VERSION "created by canmatrix"

NS_ :

BS_:

BU_: User ADM_PC_LL25 ADM_PC_BC25 ADM_PC_BP25 ADM_PC_BI25

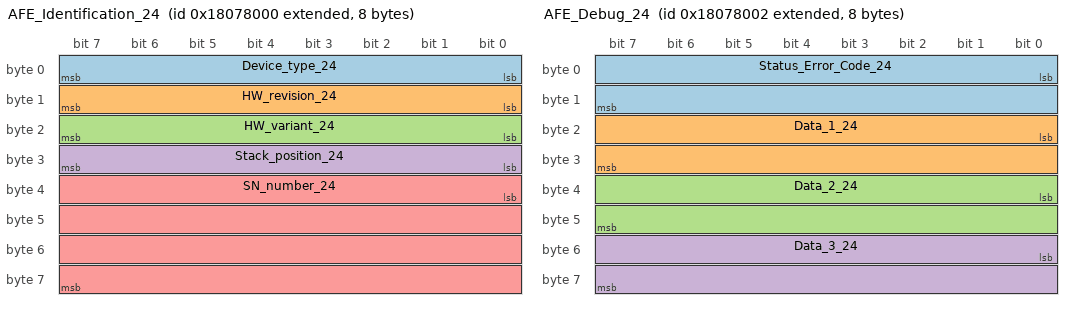
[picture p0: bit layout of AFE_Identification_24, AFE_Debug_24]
BO_ 2550628352 AFE_Identification_24: 8 ADM_PC_BP25
 SG_ Device_type_24 : 0|8@1+ (1,0) [0|255] "" Vector__XXX
 SG_ HW_revision_24 : 8|8@1+ (1,0) [0|255] "" Vector__XXX
 SG_ HW_variant_24 : 16|8@1+ (1,0) [0|255] "" Vector__XXX
 SG_ Stack_position_24 : 24|8@1+ (1,0) [0|255] "" Vector__XXX
 SG_ SN_number_24 : 32|32@1+ (1,0) [0|4294967295] "" Vector__XXX

BO_ 2550628353 AFE_FwInfo_24: 8 ADM_PC_BP25
 SG_ FW_info_mux_24 M : 56|8@1+ (1,0) [0|255] "" Vector__XXX
 SG_ FW_revision_0_24 m0 : 0|8@1+ (1,0) [0|255] "" Vector__XXX
 SG_ FW_revision_1_24 m0 : 8|8@1+ (1,0) [0|255] "" Vector__XXX
 SG_ FW_revision_2_24 m0 : 16|8@1+ (1,0) [0|255] "" Vector__XXX
 SG_ FW_revision_3_24 m0 : 24|8@1+ (1,0) [0|255] "" Vector__XXX
 SG_ FW_revision_4_24 m0 : 32|8@1+ (1,0) [0|255] "" Vector__XXX
 SG_ FW_revision_5_24 m0 : 40|8@1+ (1,0) [0|255] "" Vector__XXX
 SG_ FW_revision_6_24 m0 : 48|8@1+ (1,0) [0|255] "" Vector__XXX
 SG_ FW_revision_7_24 m1 : 0|8@1+ (1,0) [0|255] "" Vector__XXX
 SG_ FW_revision_8_24 m1 : 8|8@1+ (1,0) [0|255] "" Vector__XXX
 SG_ FW_revision_9_24 m1 : 16|8@1+ (1,0) [0|255] "" Vector__XXX
 SG_ FW_revision_10_24 m1 : 24|8@1+ (1,0) [0|255] "" Vector__XXX
 SG_ FW_revision_11_24 m1 : 32|8@1+ (1,0) [0|255] "" Vector__XXX
 SG_ FW_revision_12_24 m1 : 40|8@1+ (1,0) [0|255] "" Vector__XXX
 SG_ FW_revision_13_24 m1 : 48|8@1+ (1,0) [0|255] "" Vector__XXX
 SG_ FW_datecode_0_24 m2 : 0|8@1+ (1,0) [0|255] "" Vector__XXX
 SG_ FW_datecode_1_24 m2 : 8|8@1+ (1,0) [0|255] "" Vector__XXX
 SG_ FW_datecode_2_24 m2 : 16|8@1+ (1,0) [0|255] "" Vector__XXX
 SG_ FW_datecode_3_24 m2 : 24|8@1+ (1,0) [0|255] "" Vector__XXX
 SG_ FW_datecode_4_24 m2 : 32|8@1+ (1,0) [0|255] "" Vector__XXX
 SG_ FW_datecode_5_24 m2 : 40|8@1+ (1,0) [0|255] "" Vector__XXX
 SG_ FW_datecode_6_24 m2 : 48|8@1+ (1,0) [0|255] "" Vector__XXX
 SG_ FW_datecode_7_24 m3 : 0|8@1+ (1,0) [0|255] "" Vector__XXX
 SG_ FW_datecode_8_24 m3 : 8|8@1+ (1,0) [0|255] "" Vector__XXX
 SG_ FW_datecode_9_24 m3 : 16|8@1+ (1,0) [0|255] "" Vector__XXX
 SG_ FW_datecode_10_24 m3 : 24|8@1+ (1,0) [0|255] "" Vector__XXX
 SG_ FW_datecode_11_24 m3 : 32|8@1+ (1,0) [0|255] "" Vector__XXX
 SG_ FW_datecode_12_24 m3 : 40|8@1+ (1,0) [0|255] "" Vector__XXX
 SG_ FW_datecode_13_24 m3 : 48|8@1+ (1,0) [0|255] "" Vector__XXX

BO_ 2550628365 _AFE_Boot_FwInfo_24: 8 ADM_PC_BP25
 SG_ Boot_FW_info_mux_24 M : 56|8@1+ (1,0) [0|255] "" Vector__XXX
 SG_ FW_revision_0_24 m0 : 0|8@1+ (1,0) [0|255] "" Vector__XXX
 SG_ FW_revision_1_24 m0 : 8|8@1+ (1,0) [0|255] "" Vector__XXX
 SG_ FW_revision_2_24 m0 : 16|8@1+ (1,0) [0|255] "" Vector__XXX
 SG_ FW_revision_3_24 m0 : 24|8@1+ (1,0) [0|255] "" Vector__XXX
 SG_ FW_revision_4_24 m0 : 32|8@1+ (1,0) [0|255] "" Vector__XXX
 SG_ FW_revision_5_24 m0 : 40|8@1+ (1,0) [0|255] "" Vector__XXX
 SG_ FW_revision_6_24 m0 : 48|8@1+ (1,0) [0|255] "" Vector__XXX
 SG_ FW_revision_7_24 m1 : 0|8@1+ (1,0) [0|255] "" Vector__XXX
 SG_ FW_revision_8_24 m1 : 8|8@1+ (1,0) [0|255] "" Vector__XXX
 SG_ FW_revision_9_24 m1 : 16|8@1+ (1,0) [0|255] "" Vector__XXX
 SG_ FW_revision_10_24 m1 : 24|8@1+ (1,0) [0|255] "" Vector__XXX
 SG_ FW_revision_11_24 m1 : 32|8@1+ (1,0) [0|255] "" Vector__XXX
 SG_ FW_revision_12_24 m1 : 40|8@1+ (1,0) [0|255] "" Vector__XXX
 SG_ FW_revision_13_24 m1 : 48|8@1+ (1,0) [0|255] "" Vector__XXX
 SG_ FW_datecode_0_24 m2 : 0|8@1+ (1,0) [0|255] "" Vector__XXX
 SG_ FW_datecode_1_24 m2 : 8|8@1+ (1,0) [0|255] "" Vector__XXX
 SG_ FW_datecode_2_24 m2 : 16|8@1+ (1,0) [0|255] "" Vector__XXX
 SG_ FW_datecode_3_24 m2 : 24|8@1+ (1,0) [0|255] "" Vector__XXX
 SG_ FW_datecode_4_24 m2 : 32|8@1+ (1,0) [0|255] "" Vector__XXX
 SG_ FW_datecode_5_24 m2 : 40|8@1+ (1,0) [0|255] "" Vector__XXX
 SG_ FW_datecode_6_24 m2 : 48|8@1+ (1,0) [0|255] "" Vector__XXX
 SG_ FW_datecode_7_24 m3 : 0|8@1+ (1,0) [0|255] "" Vector__XXX
 SG_ FW_datecode_8_24 m3 : 8|8@1+ (1,0) [0|255] "" Vector__XXX
 SG_ FW_datecode_9_24 m3 : 16|8@1+ (1,0) [0|255] "" Vector__XXX
 SG_ FW_datecode_10_24 m3 : 24|8@1+ (1,0) [0|255] "" Vector__XXX
 SG_ FW_datecode_11_24 m3 : 32|8@1+ (1,0) [0|255] "" Vector__XXX
 SG_ FW_datecode_12_24 m3 : 40|8@1+ (1,0) [0|255] "" Vector__XXX
 SG_ FW_datecode_13_24 m3 : 48|8@1+ (1,0) [0|255] "" Vector__XXX

BO_ 2550628354 AFE_Debug_24: 8 ADM_PC_BP25
 SG_ Status_Error_Code_24 : 0|16@1+ (1,0) [0|65535] "" Vector__XXX
 SG_ Data_1_24 : 16|16@1+ (1,0) [0|65535] "" Vector__XXX
 SG_ Data_2_24 : 32|16@1+ (1,0) [0|65535] "" Vector__XXX
 SG_ Data_3_24 : 48|16@1+ (1,0) [0|65535] "" Vector__XXX

BO_ 2550628359 AFE_Status_24: 8 ADM_PC_BP25
 SG_ Running_24 : 0|1@1+ (1,0) [0|1] "" Vector__XXX
 SG_ PWM_24 : 1|1@1+ (1,0) [0|1] "" Vector__XXX
 SG_ Current_dc_loop_mode_24 : 2|1@1+ (1,0) [0|1] "" Vector__XXX
 SG_ Current_ac_loop_mode_24 : 3|1@1+ (1,0) [0|1] "" Vector__XXX
 SG_ Buck_24 : 5|1@1+ (1,0) [0|1] "" Vector__XXX
 SG_ Boost_24 : 6|1@1+ (1,0) [0|1] "" Vector__XXX
 SG_ Precharge_dc_buck_mode_24 : 7|1@1+ (1,0) [0|1] "" Vector__XXX
 SG_ Precharge_dc_boost_mode_24 : 8|1@1+ (1,0) [0|1] "" Vector__XXX
 SG_ Rectifier_3ph_24 : 9|1@1+ (1,0) [0|1] "" Vector__XXX
 SG_ Stack_mode_24 : 10|1@1+ (1,0) [0|1] "" Vector__XXX
 SG_ Master_24 : 11|1@1+ (1,0) [0|1] "" Vector__XXX
 SG_ Slave_24 : 12|1@1+ (1,0) [0|1] "" Vector__XXX
 SG_ Inverter_1ph_24 : 13|1@1+ (1,0) [0|1] "" Vector__XXX
 SG_ Boost_Neutral_24 : 14|1@1+ (1,0) [0|1] "" Vector__XXX
 SG_ Rectifier_1ph_24 : 15|1@1+ (1,0) [0|1] "" Vector__XXX
 SG_ Inverter_3ph_24 : 16|1@1+ (1,0) [0|1] "" Vector__XXX
 SG_ Ready_24 : 17|1@1+ (1,0) [0|1] "" Vector__XXX
 SG_ Inverter_1ph_Sync_24 : 18|1@1+ (1,0) [0|1] "" Vector__XXX
 SG_ Neutral_24 : 19|1@1+ (1,0) [0|1] "" Vector__XXX
 SG_ Rectifier_1ph_Buck_24 : 20|1@1+ (1,0) [0|1] "" Vector__XXX
 SG_ Inverter_1ph_Boost_24 : 21|1@1+ (1,0) [0|1] "" Vector__XXX
 SG_ Rectifier_distributed_24 : 22|1@1+ (1,0) [0|1] "" Vector__XXX
 SG_ MPPT_buck_24 : 23|1@1+ (1,0) [0|1] "" Vector__XXX
 SG_ MPPT_boost_24 : 24|1@1+ (1,0) [0|1] "" Vector__XXX
 SG_ Buck_2p_float_24 : 25|1@1+ (1,0) [0|1] "" Vector__XXX
 SG_ Inverter_1ph_Distributed_24 : 26|1@1+ (1,0) [0|1] "" Vector__XXX

BO_ 2550628358 AFE_Faults_24: 3 ADM_PC_BP25
 SG_ Protection_trip_internal_24 : 0|1@1+ (1,0) [0|1] "" Vector__XXX
 SG_ Protection_trip_external_24 : 1|1@1+ (1,0) [0|1] "" Vector__XXX
 SG_ Phase_U_overcurrent_24 : 2|1@1+ (1,0) [0|1] "" Vector__XXX
 SG_ Phase_U_overvoltage_24 : 3|1@1+ (1,0) [0|1] "" Vector__XXX
 SG_ Phase_U_undervoltage_24 : 4|1@1+ (1,0) [0|1] "" Vector__XXX
 SG_ Phase_V_overvoltage_24 : 5|1@1+ (1,0) [0|1] "" Vector__XXX
 SG_ Phase_V_undervoltage_24 : 6|1@1+ (1,0) [0|1] "" Vector__XXX
 SG_ Phase_V_overcurrent_24 : 7|1@1+ (1,0) [0|1] "" Vector__XXX
 SG_ Phase_W_overvoltage_24 : 8|1@1+ (1,0) [0|1] "" Vector__XXX
 SG_ Phase_W_undervoltage_24 : 9|1@1+ (1,0) [0|1] "" Vector__XXX
 SG_ Phase_W_overcurrent_24 : 10|1@1+ (1,0) [0|1] "" Vector__XXX
 SG_ DC_undervoltage_24 : 11|1@1+ (1,0) [0|1] "" Vector__XXX
 SG_ DC_overvoltage_24 : 12|1@1+ (1,0) [0|1] "" Vector__XXX
 SG_ MOSFET_overtemperature_24 : 13|1@1+ (1,0) [0|1] "" Vector__XXX
 SG_ Inductor_overtemperature_24 : 14|1@1+ (1,0) [0|1] "" Vector__XXX
 SG_ Keep_Alive_not_served_24 : 15|1@1+ (1,0) [0|1] "" Vector__XXX
 SG_ PLL_not_locked_24 : 16|1@1+ (1,0) [0|1] "" Vector__XXX
 SG_ NFO_24 : 20|1@1+ (1,0) [0|1] "" Vector__XXX
 SG_ Measurement_system_failure_24 : 21|1@1+ (1,0) [0|1] "" Vector__XXX
 SG_ EEPROM_failure_24 : 22|1@1+ (1,0) [0|1] "" Vector__XXX
 SG_ System_24 : 23|1@1+ (1,0) [0|1] "" Vector__XXX

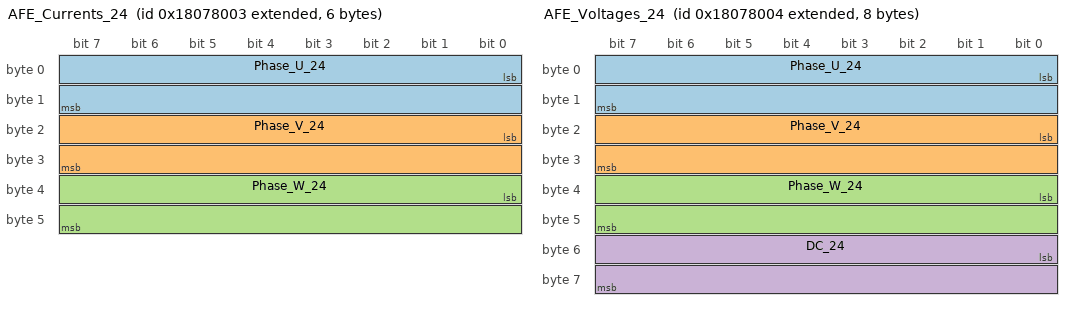
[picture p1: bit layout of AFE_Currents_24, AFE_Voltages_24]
BO_ 2550628355 AFE_Currents_24: 6 ADM_PC_BP25
 SG_ Phase_U_24 : 0|16@1- (0.01,0) [-327.68|327.67] "A" Vector__XXX
 SG_ Phase_V_24 : 16|16@1- (0.01,0) [-327.68|327.67] "A" Vector__XXX
 SG_ Phase_W_24 : 32|16@1- (0.01,0) [-327.68|327.67] "A" Vector__XXX

BO_ 2550628368 AFE_DC_Bus_current_24: 2 ADM_PC_BP25
 SG_ Bus_current_24 : 0|16@1- (0.01,0) [-327.68|327.67] "A" Vector__XXX

BO_ 2550628366 _AFE_Broadcast_24: 8 ADM_PC_BP25
 SG_ Diagnostics_Index_24 M : 56|8@1+ (1,0) [0|255] "" Vector__XXX
 SG_ Phase_U_24 m1 : 8|16@1- (0.01,0) [-327.68|327.67] "A" ADM_PC_BP25
 SG_ Phase_V_24 m1 : 24|16@1- (0.01,0) [-327.68|327.67] "A" ADM_PC_BP25
 SG_ Phase_W_24 m1 : 40|16@1- (0.01,0) [-327.68|327.67] "A" ADM_PC_BP25
 SG_ Stack_position_24 : 0|5@1+ (1,0) [0|31] "" ADM_PC_BP25
 SG_ Group_ID_24 : 5|3@1+ (1,0) [0|7] "" ADM_PC_BP25

BO_ 2550628356 AFE_Voltages_24: 8 ADM_PC_BP25
 SG_ Phase_U_24 : 0|16@1- (0.1,0) [-3276.8|3276.7] "V" Vector__XXX
 SG_ Phase_V_24 : 16|16@1- (0.1,0) [-3276.8|3276.7] "V" Vector__XXX
 SG_ Phase_W_24 : 32|16@1- (0.1,0) [-3276.8|3276.7] "V" Vector__XXX
 SG_ DC_24 : 48|16@1- (0.1,0) [-3276.8|3276.7] "V" Vector__XXX

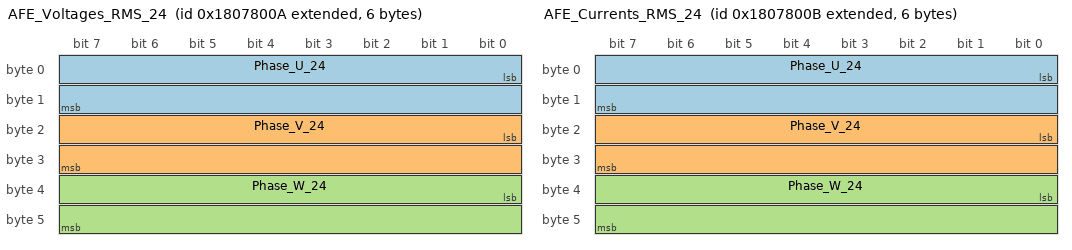
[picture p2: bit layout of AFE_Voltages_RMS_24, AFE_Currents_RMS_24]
BO_ 2550628362 AFE_Voltages_RMS_24: 6 ADM_PC_BP25
 SG_ Phase_U_24 : 0|16@1+ (0.1,0) [0|6553.5] "V" Vector__XXX
 SG_ Phase_V_24 : 16|16@1+ (0.1,0) [0|6553.5] "V" Vector__XXX
 SG_ Phase_W_24 : 32|16@1+ (0.1,0) [0|6553.5] "V" Vector__XXX

BO_ 2550628363 AFE_Currents_RMS_24: 6 ADM_PC_BP25
 SG_ Phase_U_24 : 0|16@1+ (0.01,0) [0.00|655.35] "A" Vector__XXX
 SG_ Phase_V_24 : 16|16@1+ (0.01,0) [0.00|655.35] "A" Vector__XXX
 SG_ Phase_W_24 : 32|16@1+ (0.01,0) [0.00|655.35] "A" Vector__XXX

BO_ 2550628364 AFE_Mains_24: 4 ADM_PC_BP25
 SG_ Frequency_24 : 0|16@1+ (0.01,0) [0.00|655.35] "Hz" Vector__XXX
 SG_ Phase_24 : 16|16@1- (0.1,0) [-3276.8|3276.7] "Deg." Vector__XXX

BO_ 2550628357 AFE_Temperatures_24: 4 ADM_PC_BP25
 SG_ Temp_Bridge_24 : 0|16@1- (0.01,0) [-327.68|327.67] "°C" Vector__XXX
 SG_ Temp_Inductors_24 : 16|16@1- (0.01,0) [-327.68|327.67] "°C" Vector__XXX

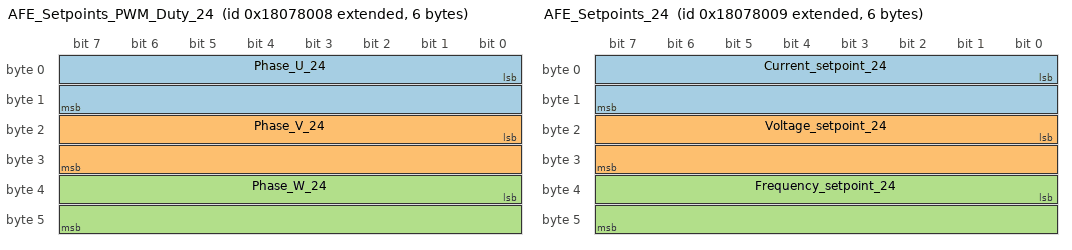
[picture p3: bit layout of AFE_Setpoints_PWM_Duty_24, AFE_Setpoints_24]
BO_ 2550628360 AFE_Setpoints_PWM_Duty_24: 6 ADM_PC_BP25
 SG_ Phase_U_24 : 0|16@1+ (0.001525902,0) [0E-009|99.999987570] "%" Vector__XXX
 SG_ Phase_V_24 : 16|16@1+ (0.001525902,0) [0E-009|99.999987570] "%" Vector__XXX
 SG_ Phase_W_24 : 32|16@1+ (0.001525902,0) [0E-009|99.999987570] "%" Vector__XXX

BO_ 2550628361 AFE_Setpoints_24: 6 ADM_PC_BP25
 SG_ Current_setpoint_24 : 0|16@1- (0.01,0) [-327.68|327.67] "A" Vector__XXX
 SG_ Voltage_setpoint_24 : 16|16@1+ (0.1,0) [0|6553.5] "V" Vector__XXX
 SG_ Frequency_setpoint_24 : 32|16@1+ (0.01,0) [0.00|655.35] "Hz" Vector__XXX

BO_ 2550595680 AFE_Keep_Alive_24: 1 User
 SG_ Keep_Alive_Enable_24 : 0|1@1+ (1,0) [0|1] "" ADM_PC_BP25

BO_ 2550595648 AFE_Mode_Control_24: 8 User
 SG_ Converter_ON_24 : 0|1@1+ (1,0) [0|1] "" ADM_PC_BP25
 SG_ PWM_ON_24 : 1|1@1+ (1,0) [0|1] "" ADM_PC_BP25
 SG_ DC_Current_feedback_ON_24 : 2|1@1+ (1,0) [0|1] "" ADM_PC_BP25
 SG_ AC_Current_feedback_ON_24 : 3|1@1+ (1,0) [0|1] "" ADM_PC_BP25
 SG_ Buck_ON_24 : 5|1@1+ (1,0) [0|1] "" ADM_PC_BP25
 SG_ Boost_ON_24 : 6|1@1+ (1,0) [0|1] "" ADM_PC_BP25
 SG_ Rectifier_3ph_ON_24 : 9|1@1+ (1,0) [0|1] "" ADM_PC_BP25
 SG_ Inverter_1ph_ON_24 : 10|1@1+ (1,0) [0|1] "" ADM_PC_BP25
 SG_ Rectifier_1ph_ON_24 : 11|1@1+ (1,0) [0|1] "" ADM_PC_BP25
 SG_ Boost_Neutral_ON_24 : 12|1@1+ (1,0) [0|1] "" ADM_PC_BP25
 SG_ Inverter_3ph_ON_24 : 13|1@1+ (1,0) [0|1] "" ADM_PC_BP25
 SG_ Inverter_1ph_Sync_ON_24 : 14|1@1+ (1,0) [0|1] "" ADM_PC_BP25
 SG_ Neutral_ON_24 : 15|1@1+ (1,0) [0|1] "" ADM_PC_BP25
 SG_ Rectifier_1ph_Buck_ON_24 : 16|1@1+ (1,0) [0|1] "" ADM_PC_BP25
 SG_ Inverter_1ph_Boost_ON_24 : 17|1@1+ (1,0) [0|1] "" ADM_PC_BP25
 SG_ Rectifier_Distributed_ON_24 : 18|1@1+ (1,0) [0|1] "" ADM_PC_BP25
 SG_ MPPT_buck_ON_24 : 19|1@1+ (1,0) [0|1] "" ADM_PC_BP25
 SG_ MPPT_boost_ON_24 : 20|1@1+ (1,0) [0|1] "" ADM_PC_BP25
 SG_ Buck_2p_float_ON_24 : 21|1@1+ (1,0) [0|1] "" ADM_PC_BP25
 SG_ Inverter_1ph_Distributed_ON_24 : 22|1@1+ (1,0) [0|1] "" ADM_PC_BP25

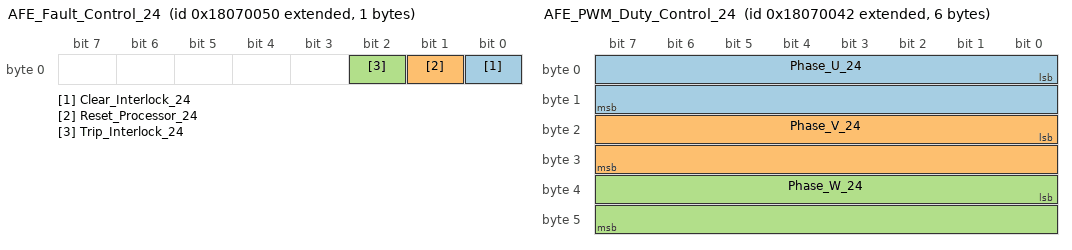
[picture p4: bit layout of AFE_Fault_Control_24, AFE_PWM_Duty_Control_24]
BO_ 2550595664 AFE_Fault_Control_24: 1 User
 SG_ Clear_Interlock_24 : 0|1@1+ (1,0) [0|1] "" ADM_PC_BP25
 SG_ Reset_Processor_24 : 1|1@1+ (1,0) [0|1] "" ADM_PC_BP25
 SG_ Trip_Interlock_24 : 2|1@1+ (1,0) [0|1] "" ADM_PC_BP25

BO_ 2550595649 AFE_Reactive_Current_Setpoint_Co: 2 User
 SG_ Reactive_current_setpoint_24 : 0|16@1- (0.01,0) [-150|150] "A" ADM_PC_BP25

BO_ 2550595650 AFE_PWM_Duty_Control_24: 6 User
 SG_ Phase_U_24 : 0|16@1+ (0.001525902,0) [0E-009|99.999987570] "%" ADM_PC_BP25
 SG_ Phase_V_24 : 16|16@1+ (0.001525902,0) [0E-009|99.999987570] "%" ADM_PC_BP25
 SG_ Phase_W_24 : 32|16@1+ (0.001525902,0) [0E-009|99.999987570] "%" ADM_PC_BP25

BO_ 2550595651 AFE_Current_Setpoint_Control_24: 2 User
 SG_ Current_setpoint_24 : 0|16@1- (0.01,0) [-150|150] "A" ADM_PC_BP25

BO_ 2550595652 AFE_Voltage_Setpoint_Control_24: 2 User
 SG_ Voltage_setpoint_24 : 0|16@1+ (0.1,0) [0|1500] "V" ADM_PC_BP25

BO_ 2550595656 AFE_Frequency_Setpoint_Control_2: 2 User
 SG_ Frequency_setpoint_24 : 0|16@1+ (0.01,0) [40|70] "Hz" ADM_PC_BP25

BO_ 2550595657 AFE_Phase_Setpoint_Control_24: 2 User
 SG_ Phase_setpoint_24 : 0|16@1+ (1,0) [0|360] "deg" ADM_PC_BP25

BO_ 2550595696 AFE_Rectifier_Setpoint_Control_2: 8 User
 SG_ Voltage_setpoint_2_24 : 0|16@1+ (0.1,0) [0|1500] "V" ADM_PC_BP25
 SG_ Current_setpoint_2_24 : 16|16@1- (0.01,0) [-150|150] "A" ADM_PC_BP25

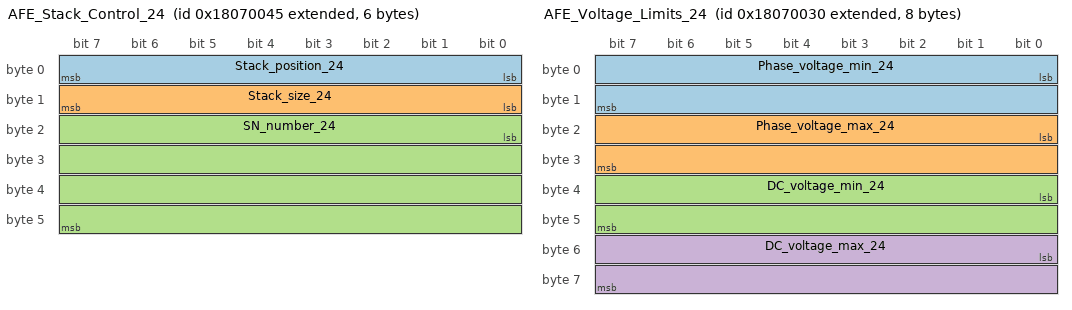
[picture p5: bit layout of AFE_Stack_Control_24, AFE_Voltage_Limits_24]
BO_ 2550595653 AFE_Stack_Control_24: 6 User
 SG_ Stack_position_24 : 0|8@1+ (1,0) [0|255] "" ADM_PC_BP25
 SG_ Stack_size_24 : 8|8@1+ (1,0) [0|255] "" ADM_PC_BP25
 SG_ SN_number_24 : 16|32@1+ (1,0) [0|4294967295] "" ADM_PC_BP25

BO_ 2550595632 AFE_Voltage_Limits_24: 8 User
 SG_ Phase_voltage_min_24 : 0|16@1- (0.1,0) [0|3276.7] "V" ADM_PC_BP25
 SG_ Phase_voltage_max_24 : 16|16@1- (0.1,0) [-3276.8|850] "V" ADM_PC_BP25
 SG_ DC_voltage_min_24 : 32|16@1- (0.1,0) [0|3276.7] "V" ADM_PC_BP25
 SG_ DC_voltage_max_24 : 48|16@1- (0.1,0) [-3276.8|850] "V" ADM_PC_BP25

BO_ 2550595633 AFE_Current_Limits_24: 4 User
 SG_ Phase_current_min_24 : 0|16@1- (0.01,0) [-60|60] "A" ADM_PC_BP25
 SG_ Phase_current_max_24 : 16|16@1- (0.01,0) [-60|60] "A" ADM_PC_BP25

BO_ 2550595660 AFE_Group_Control_24: 1 User
 SG_ Group_ID_24 : 0|8@1+ (1,0) [0|255] "" ADM_PC_BP25

BO_ 2550628367 AFE_Group_Info_24: 1 ADM_PC_BP25
 SG_ Group_ID_24 : 0|8@1+ (1,0) [0|255] "" Vector__XXX

BO_ 2550595681 AFE_System_Flags_Control_24: 8 User
 SG_ Factory_mode_24 : 0|1@1+ (1,0) [0|1] "" ADM_PC_BP25
 SG_ Silent_CAN_mode_24 : 1|1@1+ (1,0) [0|1] "" ADM_PC_BP25

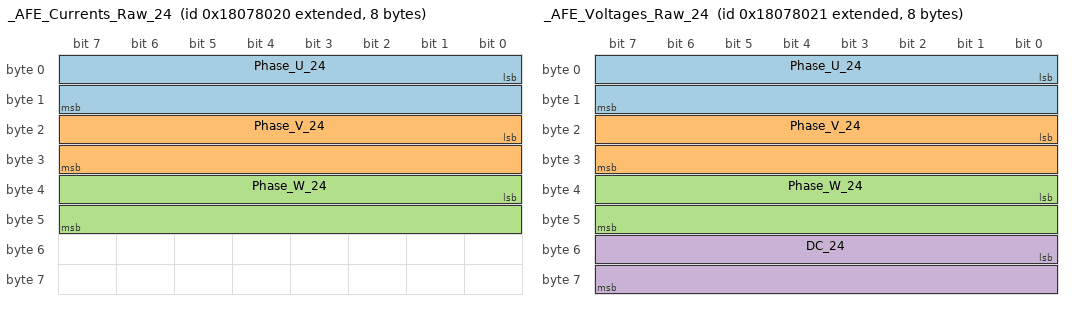
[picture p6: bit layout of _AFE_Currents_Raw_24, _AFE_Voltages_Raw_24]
BO_ 2550628384 _AFE_Currents_Raw_24: 8 ADM_PC_BP25
 SG_ Phase_U_24 : 0|16@1- (1,0) [-32768|32767] "" Vector__XXX
 SG_ Phase_V_24 : 16|16@1- (1,0) [-32768|32767] "" Vector__XXX
 SG_ Phase_W_24 : 32|16@1- (1,0) [-32768|32767] "" Vector__XXX

BO_ 2550628385 _AFE_Voltages_Raw_24: 8 ADM_PC_BP25
 SG_ Phase_U_24 : 0|16@1- (1,0) [-32768|32767] "" Vector__XXX
 SG_ Phase_V_24 : 16|16@1- (1,0) [-32768|32767] "" Vector__XXX
 SG_ Phase_W_24 : 32|16@1- (1,0) [-32768|32767] "" Vector__XXX
 SG_ DC_24 : 48|16@1- (1,0) [-32768|32767] "" Vector__XXX

BO_ 2550595658 _AFE_ADC_Calibration_Mode_24: 1 User
 SG_ Calibration_Index_24 M : 2|5@1+ (1,0) [0|31] "" Vector__XXX
 SG_ Current_U_24 m1 : 0|2@1+ (1,0) [0|3] "" ADM_PC_BP25
 SG_ Current_V_24 m2 : 0|2@1+ (1,0) [0|3] "" ADM_PC_BP25
 SG_ Current_W_24 m3 : 0|2@1+ (1,0) [0|3] "" ADM_PC_BP25
 SG_ Voltage_U_24 m4 : 0|2@1+ (1,0) [0|3] "" ADM_PC_BP25
 SG_ Voltage_V_24 m5 : 0|2@1+ (1,0) [0|3] "" ADM_PC_BP25
 SG_ Voltage_W_24 m6 : 0|2@1+ (1,0) [0|3] "" ADM_PC_BP25
 SG_ Voltage_DC_24 m7 : 0|2@1+ (1,0) [0|3] "" ADM_PC_BP25
 SG_ start_24 : 7|1@1+ (1,0) [0|1] "" ADM_PC_BP25

BO_ 2550595659 _AFE_ADC_Calibration_Setpoint_24: 3 User
 SG_ Calibration_Index_24 M : 16|5@1+ (1,0) [0|31] "" Vector__XXX
 SG_ Current_U_24 m1 : 0|16@1- (0.01,0) [-100|100] "A" ADM_PC_BP25
 SG_ Current_V_24 m2 : 0|16@1- (0.01,0) [-100|100] "A" ADM_PC_BP25
 SG_ Current_W_24 m3 : 0|16@1- (0.01,0) [-100|100] "A" ADM_PC_BP25
 SG_ Voltage_U_24 m4 : 0|16@1+ (0.1,0) [0|1500] "V" ADM_PC_BP25
 SG_ Voltage_V_24 m5 : 0|16@1+ (0.1,0) [0|1500] "V" ADM_PC_BP25
 SG_ Voltage_W_24 m6 : 0|16@1+ (0.1,0) [0|1500] "V" ADM_PC_BP25
 SG_ Voltage_DC_24 m7 : 0|16@1+ (0.1,0) [0|1500] "V" ADM_PC_BP25
 SG_ point_24 : 21|3@1+ (1,0) [0|7] "" ADM_PC_BP25

BO_ 2550595654 _AFE_Calibration_Offset_Update_2: 6 User
 SG_ Calibration_Index_24 M : 16|16@1+ (1,0) [0|65535] "" Vector__XXX
 SG_ Current_U_24 m0 : 0|16@1- (1,0) [-32768|32767] "ADC Counts" ADM_PC_BP25
 SG_ Current_V_24 m1 : 0|16@1- (1,0) [-32768|32767] "ADC Counts" ADM_PC_BP25
 SG_ Current_W_24 m2 : 0|16@1- (1,0) [-32768|32767] "ADC Counts" ADM_PC_BP25
 SG_ Voltage_U_24 m3 : 0|16@1- (1,0) [-32768|32767] "ADC Counts" ADM_PC_BP25
 SG_ Voltage_V_24 m4 : 0|16@1- (1,0) [-32768|32767] "ADC Counts" ADM_PC_BP25
 SG_ Voltage_W_24 m5 : 0|16@1- (1,0) [-32768|32767] "ADC Counts" ADM_PC_BP25
 SG_ Voltage_DC_24 m6 : 0|16@1- (1,0) [-32768|32767] "ADC Counts" ADM_PC_BP25
 SG_ CRC_24 : 32|16@1+ (1,0) [0|65535] "-" ADM_PC_BP25

BO_ 2550595655 _AFE_Calibration_Scale_Update_24: 6 User
 SG_ Calibration_Index_24 M : 16|16@1+ (1,0) [0|65535] "" Vector__XXX
 SG_ Current_U_24 m0 : 0|16@1- (0.0000152587890625,0) [-0.5000000000000000|0.4999847412109375] "scale = 1.0 + value" ADM_PC_BP25
 SG_ Current_V_24 m1 : 0|16@1- (0.0000152587890625,0) [-0.5000000000000000|0.4999847412109375] "scale = 1.0 + value" ADM_PC_BP25
 SG_ Current_W_24 m2 : 0|16@1- (0.0000152587890625,0) [-0.5000000000000000|0.4999847412109375] "scale = 1.0 + value" ADM_PC_BP25
 SG_ Voltage_U_24 m3 : 0|16@1- (0.0000152587890625,0) [-0.5000000000000000|0.4999847412109375] "scale = 1.0 + value" ADM_PC_BP25
 SG_ Voltage_V_24 m4 : 0|16@1- (0.0000152587890625,0) [-0.5000000000000000|0.4999847412109375] "scale = 1.0 + value" ADM_PC_BP25
 SG_ Voltage_W_24 m5 : 0|16@1- (0.0000152587890625,0) [-0.5000000000000000|0.4999847412109375] "scale = 1.0 + value" ADM_PC_BP25
 SG_ Voltage_DC_24 m6 : 0|16@1- (0.0000152587890625,0) [-0.5000000000000000|0.4999847412109375] "scale = 1.0 + value" ADM_PC_BP25
 SG_ CRC_24 : 32|16@1+ (1,0) [0|65535] "-" ADM_PC_BP25

BO_ 2550628433 _AFE_Calibration_Adc_Scale_24: 6 ADM_PC_BP25
 SG_ Adc_Index_24 M : 32|16@1+ (1,0) [0|65535] "" Vector__XXX
 SG_ Current_U_24 m0 : 0|32@1+ (1,0) [0|4294967295] "1 / adc_bins" User
 SG_ Current_V_24 m1 : 0|32@1+ (1,0) [0|4294967295] "1 / adc_bins" User
 SG_ Current_W_24 m2 : 0|32@1+ (1,0) [0|4294967295] "1 / adc_bins" User
 SG_ Voltage_U_24 m3 : 0|32@1+ (1,0) [0|4294967295] "1 / adc_bins" User
 SG_ Voltage_V_24 m4 : 0|32@1+ (1,0) [0|4294967295] "1 / adc_bins" User
 SG_ Voltage_W_24 m5 : 0|32@1+ (1,0) [0|4294967295] "1 / adc_bins" User
 SG_ Voltage_DC_24 m6 : 0|32@1+ (1,0) [0|4294967295] "1 / adc_bins" User

BO_ 2550628434 _AFE_Calibration_Adc_Fs_24: 6 ADM_PC_BP25
 SG_ Adc_Index_24 M : 32|16@1+ (1,0) [0|65535] "" Vector__XXX
 SG_ Current_U_24 m0 : 0|32@1+ (1,0) [0|4294967295] "Fullscale" User
 SG_ Current_V_24 m1 : 0|32@1+ (1,0) [0|4294967295] "Fullscale" User
 SG_ Current_W_24 m2 : 0|32@1+ (1,0) [0|4294967295] "Fullscale" User
 SG_ Voltage_U_24 m3 : 0|32@1+ (1,0) [0|4294967295] "Fullscale" User
 SG_ Voltage_V_24 m4 : 0|32@1+ (1,0) [0|4294967295] "Fullscale" User
 SG_ Voltage_W_24 m5 : 0|32@1+ (1,0) [0|4294967295] "Fullscale" User
 SG_ Voltage_DC_24 m6 : 0|32@1+ (1,0) [0|4294967295] "Fullscale" User

BO_ 2550628435 _AFE_Calibration_Adc_Offset_24: 4 ADM_PC_BP25
 SG_ Adc_Index_24 M : 16|16@1+ (1,0) [0|65535] "" Vector__XXX
 SG_ Current_U_24 m0 : 0|16@1- (1,0) [-32768|32767] "-" User
 SG_ Current_V_24 m1 : 0|16@1- (1,0) [-32768|32767] "-" User
 SG_ Current_W_24 m2 : 0|16@1- (1,0) [-32768|32767] "-" User
 SG_ Voltage_U_24 m3 : 0|16@1- (1,0) [-32768|32767] "-" User
 SG_ Voltage_V_24 m4 : 0|16@1- (1,0) [-32768|32767] "-" User
 SG_ Voltage_W_24 m5 : 0|16@1- (1,0) [-32768|32767] "-" User
 SG_ Voltage_DC_24 m6 : 0|16@1- (1,0) [-32768|32767] "-" User

BO_ 2550628436 _AFE_Calibration_Adc_Gain_24: 4 ADM_PC_BP25
 SG_ Adc_Index_24 M : 16|16@1+ (1,0) [0|65535] "" Vector__XXX
 SG_ Current_U_24 m0 : 0|16@1- (1,0) [-32768|32767] "-" User
 SG_ Current_V_24 m1 : 0|16@1- (1,0) [-32768|32767] "-" User
 SG_ Current_W_24 m2 : 0|16@1- (1,0) [-32768|32767] "-" User
 SG_ Voltage_U_24 m3 : 0|16@1- (1,0) [-32768|32767] "-" User
 SG_ Voltage_V_24 m4 : 0|16@1- (1,0) [-32768|32767] "-" User
 SG_ Voltage_W_24 m5 : 0|16@1- (1,0) [-32768|32767] "-" User
 SG_ Voltage_DC_24 m6 : 0|16@1- (1,0) [-32768|32767] "-" User

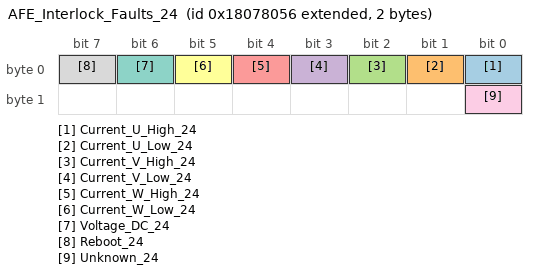
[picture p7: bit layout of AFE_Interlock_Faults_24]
BO_ 2550628438 AFE_Interlock_Faults_24: 2 ADM_PC_BP25
 SG_ Current_U_High_24 : 0|1@1+ (1,0) [0|1] "" Vector__XXX
 SG_ Current_U_Low_24 : 1|1@1+ (1,0) [0|1] "" Vector__XXX
 SG_ Current_V_High_24 : 2|1@1+ (1,0) [0|1] "" Vector__XXX
 SG_ Current_V_Low_24 : 3|1@1+ (1,0) [0|1] "" Vector__XXX
 SG_ Current_W_High_24 : 4|1@1+ (1,0) [0|1] "" Vector__XXX
 SG_ Current_W_Low_24 : 5|1@1+ (1,0) [0|1] "" Vector__XXX
 SG_ Voltage_DC_24 : 6|1@1+ (1,0) [0|1] "" Vector__XXX
 SG_ Reboot_24 : 7|1@1+ (1,0) [0|1] "" Vector__XXX
 SG_ Unknown_24 : 8|1@1+ (1,0) [0|1] "" Vector__XXX

BO_TX_BU_ 2550595648 : User,ADM_PC_LL25,ADM_PC_BC25,ADM_PC_BI25;
BO_TX_BU_ 2550595651 : User,ADM_PC_LL25,ADM_PC_BC25,ADM_PC_BI25;
BO_TX_BU_ 2550595652 : User,ADM_PC_LL25,ADM_PC_BC25,ADM_PC_BI25;
CM_ BO_ 2550628352  "Identification of the device";
CM_ BO_ 2550628353  "Git revision of the DSP firmware";
CM_ BO_ 2550628365  "Git revision of the bootloader firmware.";
CM_ BO_ 2550628354  "Values for debugging of HW/SW problems";
CM_ BO_ 2550628359  "Status bitfield";
CM_ BO_ 2550628358  "Fault bitfield";
CM_ BO_ 2550628355  "Current of phases U, V, W";
CM_ BO_ 2550628368  "Current of of the DC Bus";
CM_ BO_ 2550628366  "All AFEs will listen to this message";
CM_ BO_ 2550628363  "RMS Current of phases U, V, W";
CM_ BO_ 2550628364  "Three-Phase mains health (frequency, phase...)";
CM_ BO_ 2550628357  "Readouts of the module temperature sensors";
CM_ BO_ 2550628360  "Setpoints";
CM_ BO_ 2550628361  "Setpoints";
CM_ BO_ 2550595680  "Keep alive ping message. ";
CM_ BO_ 2550595648  "Operation Mode control: sets the converter operation mode";
CM_ BO_ 2550595664  "Fault Control: actions to clear faults and reset the system";
CM_ BO_ 2550595649  "Reactive power setpoint control.";
CM_ BO_ 2550595650  "PWM duty cycle control";
CM_ BO_ 2550595651  "Current setpoint control";
CM_ BO_ 2550595652  "Voltage setpoint control";
CM_ BO_ 2550595656  "Frequency setpoint control";
CM_ BO_ 2550595657  "Phase setpoint control";
CM_ BO_ 2550595696  "Additional voltage and current setpoints in single-phase rectifier and inverter control modes.";
CM_ BO_ 2550595653  "PFC stack control";
CM_ BO_ 2550595632  "Set the input and output voltage limits (minimum and maximum)";
CM_ BO_ 2550595633  "Set the output current limits (mminimum and maximum)";
CM_ BO_ 2550595660  "Set the Group ID of the device";
CM_ BO_ 2550628367  "Contains the Group ID of the device";
CM_ BO_ 2550595681  "Control the system flags";
CM_ BO_ 2550628384  "Current of phases A and B";
CM_ BO_ 2550628385  "Current of phases A and B";
CM_ BO_ 2550595658  "Automatic ADC calibration.";
CM_ BO_ 2550595659  "Setpoint for automatic ADC calibration.";
CM_ BO_ 2550595654  "Update of the calibration table for offsets.";
CM_ BO_ 2550595655  "Update of the calibration table for scales.";
CM_ BO_ 2550628433  "
                Adc scale (resolution) value of readouts.
            ";
CM_ BO_ 2550628434  "
                Adc fullscale value of readouts.
            ";
CM_ BO_ 2550628435  "
                Readout of ADC calibration data (offset) from EEPROM.
            ";
CM_ BO_ 2550628436  "
                Readout of ADC calibration data (gain) from EEPROM.
            ";
CM_ BO_ 2550628438  "Fault bitfield";

CM_ SG_ 2550628352 Device_type_24 "The device identification field, uniquely identifies the sender in the network";
CM_ SG_ 2550628352 HW_revision_24 "The hardware revision number";
CM_ SG_ 2550628352 HW_variant_24 "The DSP firmware revision number";
CM_ SG_ 2550628352 Stack_position_24 "Position of the module within the stack";
CM_ SG_ 2550628352 SN_number_24 "Unique module serial number";
CM_ SG_ 2550628353 FW_revision_0_24 "Character 0";
CM_ SG_ 2550628353 FW_revision_1_24 "Character 1";
CM_ SG_ 2550628353 FW_revision_2_24 "Character 2";
CM_ SG_ 2550628353 FW_revision_3_24 "Character 3";
CM_ SG_ 2550628353 FW_revision_4_24 "Character 3";
CM_ SG_ 2550628353 FW_revision_5_24 "Character 3";
CM_ SG_ 2550628353 FW_revision_6_24 "Character 3";
CM_ SG_ 2550628353 FW_revision_7_24 "Character 7";
CM_ SG_ 2550628353 FW_revision_8_24 "Character 8";
CM_ SG_ 2550628353 FW_revision_9_24 "Character 9";
CM_ SG_ 2550628353 FW_revision_10_24 "Character 10";
CM_ SG_ 2550628353 FW_revision_11_24 "Character 11";
CM_ SG_ 2550628353 FW_revision_12_24 "Character 12";
CM_ SG_ 2550628353 FW_revision_13_24 "Character 13";
CM_ SG_ 2550628353 FW_datecode_0_24 "Character 0";
CM_ SG_ 2550628353 FW_datecode_1_24 "Character 1";
CM_ SG_ 2550628353 FW_datecode_2_24 "Character 2";
CM_ SG_ 2550628353 FW_datecode_3_24 "Character 3";
CM_ SG_ 2550628353 FW_datecode_4_24 "Character 3";
CM_ SG_ 2550628353 FW_datecode_5_24 "Character 3";
CM_ SG_ 2550628353 FW_datecode_6_24 "Character 3";
CM_ SG_ 2550628353 FW_datecode_7_24 "Character 7";
CM_ SG_ 2550628353 FW_datecode_8_24 "Character 8";
CM_ SG_ 2550628353 FW_datecode_9_24 "Character 9";
CM_ SG_ 2550628353 FW_datecode_10_24 "Character 10";
CM_ SG_ 2550628353 FW_datecode_11_24 "Character 11";
CM_ SG_ 2550628353 FW_datecode_12_24 "Character 12";
CM_ SG_ 2550628353 FW_datecode_13_24 "Character 13";
CM_ SG_ 2550628365 FW_revision_0_24 "Character 0";
CM_ SG_ 2550628365 FW_revision_1_24 "Character 1";
CM_ SG_ 2550628365 FW_revision_2_24 "Character 2";
CM_ SG_ 2550628365 FW_revision_3_24 "Character 3";
CM_ SG_ 2550628365 FW_revision_4_24 "Character 3";
CM_ SG_ 2550628365 FW_revision_5_24 "Character 3";
CM_ SG_ 2550628365 FW_revision_6_24 "Character 3";
CM_ SG_ 2550628365 FW_revision_7_24 "Character 7";
CM_ SG_ 2550628365 FW_revision_8_24 "Character 8";
CM_ SG_ 2550628365 FW_revision_9_24 "Character 9";
CM_ SG_ 2550628365 FW_revision_10_24 "Character 10";
CM_ SG_ 2550628365 FW_revision_11_24 "Character 11";
CM_ SG_ 2550628365 FW_revision_12_24 "Character 12";
CM_ SG_ 2550628365 FW_revision_13_24 "Character 13";
CM_ SG_ 2550628365 FW_datecode_0_24 "Character 0";
CM_ SG_ 2550628365 FW_datecode_1_24 "Character 1";
CM_ SG_ 2550628365 FW_datecode_2_24 "Character 2";
CM_ SG_ 2550628365 FW_datecode_3_24 "Character 3";
CM_ SG_ 2550628365 FW_datecode_4_24 "Character 3";
CM_ SG_ 2550628365 FW_datecode_5_24 "Character 3";
CM_ SG_ 2550628365 FW_datecode_6_24 "Character 3";
CM_ SG_ 2550628365 FW_datecode_7_24 "Character 7";
CM_ SG_ 2550628365 FW_datecode_8_24 "Character 8";
CM_ SG_ 2550628365 FW_datecode_9_24 "Character 9";
CM_ SG_ 2550628365 FW_datecode_10_24 "Character 10";
CM_ SG_ 2550628365 FW_datecode_11_24 "Character 11";
CM_ SG_ 2550628365 FW_datecode_12_24 "Character 12";
CM_ SG_ 2550628365 FW_datecode_13_24 "Character 13";
CM_ SG_ 2550628354 Status_Error_Code_24 "Main status / error code as defined in errno/errno.h";
CM_ SG_ 2550628354 Data_1_24 "Additional information for the error/status";
CM_ SG_ 2550628354 Data_2_24 "Additional information for the error/status";
CM_ SG_ 2550628354 Data_3_24 "Additional information for the error/status";
CM_ SG_ 2550628359 Running_24 "Indicates if converter is running.";
CM_ SG_ 2550628359 PWM_24 "Indicates if converter is in PWM control mode.";
CM_ SG_ 2550628359 Current_dc_loop_mode_24 "Indicates if the current DC loop is enabled.";
CM_ SG_ 2550628359 Current_ac_loop_mode_24 "Indicates if the current AC loop is enabled.";
CM_ SG_ 2550628359 Buck_24 "Indicates if converter is in buck control mode.";
CM_ SG_ 2550628359 Boost_24 "Indicates if converter is in boost control mode.";
CM_ SG_ 2550628359 Precharge_dc_buck_mode_24 "Indicates if the precharge DC mode is enabled - buck direction.";
CM_ SG_ 2550628359 Precharge_dc_boost_mode_24 "Indicates if the precharge DC mode is enabled - boost direction.";
CM_ SG_ 2550628359 Rectifier_3ph_24 "Indicates if converter is in three-phase rectifier control mode.";
CM_ SG_ 2550628359 Stack_mode_24 "Indicates if converter is operating in stack mode.";
CM_ SG_ 2550628359 Master_24 "Indicates if converter is master in the stack.";
CM_ SG_ 2550628359 Slave_24 "Indicates if converter is slave in the stack.";
CM_ SG_ 2550628359 Inverter_1ph_24 "Indicates if converter is in single-phase inverter control mode.";
CM_ SG_ 2550628359 Boost_Neutral_24 "Indicates if converter is in boost control mode with neutral generation.";
CM_ SG_ 2550628359 Rectifier_1ph_24 "Indicates if converter is in single-phase rectifier control mode.";
CM_ SG_ 2550628359 Inverter_3ph_24 "Indicates if converter is in three-phase inverter control mode.";
CM_ SG_ 2550628359 Ready_24 "Indicates if converter is ready for operation.";
CM_ SG_ 2550628359 Inverter_1ph_Sync_24 "Single-phase inverter control mode with phase synchronization.";
CM_ SG_ 2550628359 Neutral_24 "Open-loop neutral generation.";
CM_ SG_ 2550628359 Rectifier_1ph_Buck_24 "Single-phase rectifier with buck on one leg.";
CM_ SG_ 2550628359 Inverter_1ph_Boost_24 "Single-phase inverter with boost on one leg.";
CM_ SG_ 2550628359 Rectifier_distributed_24 "Not available at the moment";
CM_ SG_ 2550628359 MPPT_buck_24 "Not available at the moment";
CM_ SG_ 2550628359 MPPT_boost_24 "Not available at the moment";
CM_ SG_ 2550628359 Buck_2p_float_24 "Buck in phases L1 and L2. Phase L3 is left floating (high impedance)";
CM_ SG_ 2550628359 Inverter_1ph_Distributed_24 "Single-phase inverter mode  distributed";
CM_ SG_ 2550628358 Protection_trip_internal_24 "This flagg is asserted if the interlock is open due to an internal fault condition (self-protection)";
CM_ SG_ 2550628358 Protection_trip_external_24 "This flag is asserted if the interlock is open due to an external condition received in the module.";
CM_ SG_ 2550628358 Phase_U_overcurrent_24 "Indicates an overcurrent event on Phase U. The overcurrent event is triggered when the measured phase current is over the programmed current limit.";
CM_ SG_ 2550628358 Phase_U_overvoltage_24 "Indicates an overvoltage event on Phase U. The overvoltage event is triggered when the measured phase voltage is over the programmed voltage limit.";
CM_ SG_ 2550628358 Phase_U_undervoltage_24 "Indicates an undervoltage event on Phase U. The overvoltage event is triggered when the measured phase voltage is over the programmed voltage limit.";
CM_ SG_ 2550628358 Phase_V_overvoltage_24 "Indicates an overvoltage event on Phase V. The overvoltage event is triggered when the measured phase voltage is over the programmed voltage limit.";
CM_ SG_ 2550628358 Phase_V_undervoltage_24 "Indicates an undervoltage event on Phase U. The overvoltage event is triggered when the measured phase voltage is over the programmed voltage limit.";
CM_ SG_ 2550628358 Phase_V_overcurrent_24 "Indicates an overcurrent event on Phase U. The overcurrent event is triggered when the measured phase current is over the programmed current limit.";
CM_ SG_ 2550628358 Phase_W_overvoltage_24 "Indicates an overvoltage event on Phase U. The overvoltage event is triggered when the measured phase voltage is over the programmed voltage limit.";
CM_ SG_ 2550628358 Phase_W_undervoltage_24 "Indicates an undervoltage event on Phase U. The overvoltage event is triggered when the measured phase voltage is over the programmed voltage limit.";
CM_ SG_ 2550628358 Phase_W_overcurrent_24 "Indicates an overcurrent event on Phase U. The overcurrent event is triggered when the measured phase current is over the programmed current limit.";
CM_ SG_ 2550628358 DC_undervoltage_24 "DC bus undervoltage condition. The undervoltage condition is asserted when the measured dc bus voltage is under the programmed voltage limit.";
CM_ SG_ 2550628358 DC_overvoltage_24 "DC bus overvoltage condition. The overvoltage condition is asserted when the measured dc bus voltage is over the programmed voltage limit.";
CM_ SG_ 2550628358 MOSFET_overtemperature_24 "This flag is asserted when the temperature of the MOSFET block is too high.";
CM_ SG_ 2550628358 Inductor_overtemperature_24 "This flag is asserted when the temperature of the inductor block is too high.";
CM_ SG_ 2550628358 Keep_Alive_not_served_24 "The Keep Alive feature is enabled but it was not served with the periodic message.";
CM_ SG_ 2550628358 PLL_not_locked_24 "Flag asserted when in rectifier modes, the PLL went out of lock condition";
CM_ SG_ 2550628358 Measurement_system_failure_24 "The voltages/currents measurement system is malfunctionning, and readouts are not guaranteed to be accurate.";
CM_ SG_ 2550628358 EEPROM_failure_24 "The configuration EEPROM failed to load or save the module configuration.";
CM_ SG_ 2550628355 Phase_U_24 "Phase current is the MOSFET loop current, in the branch U of the converter.";
CM_ SG_ 2550628355 Phase_V_24 "Phase current is the MOSFET loop current, in the branch V of the converter.";
CM_ SG_ 2550628355 Phase_W_24 "Phase current is the MOSFET loop current, in the branch W of the converter.";
CM_ SG_ 2550628368 Bus_current_24 "DC Bus current is possitive when current goes from input to output";
CM_ SG_ 2550628366 Phase_U_24 "Phase current is the MOSFET loop current, in the branch U of the converter.";
CM_ SG_ 2550628366 Phase_V_24 "Phase current is the MOSFET loop current, in the branch V of the converter.";
CM_ SG_ 2550628366 Phase_W_24 "Phase current is the MOSFET loop current, in the branch W of the converter.";
CM_ SG_ 2550628366 Stack_position_24 "Sender Stack position";
CM_ SG_ 2550628366 Group_ID_24 "Sender Group ID";
CM_ SG_ 2550628363 Phase_U_24 "RMS Phase current is the MOSFET loop current, in the branch U of the converter.";
CM_ SG_ 2550628363 Phase_V_24 "RMS Phase current is the MOSFET loop current, in the branch V of the converter.";
CM_ SG_ 2550628363 Phase_W_24 "RMS Phase current is the MOSFET loop current, in the branch W of the converter.";
CM_ SG_ 2550628364 Frequency_24 "Frequency of Three-Phase system";
CM_ SG_ 2550628364 Phase_24 "Phase of Three-Phase system";
CM_ SG_ 2550628357 Temp_Bridge_24 "Temperature of the MOSFET block";
CM_ SG_ 2550628357 Temp_Inductors_24 "Temperature of the inductors";
CM_ SG_ 2550628360 Phase_U_24 "The actual PWM duty cycle setpoint";
CM_ SG_ 2550628360 Phase_V_24 "The actual PWM duty cycle setpoint";
CM_ SG_ 2550628360 Phase_W_24 "The actual PWM duty cycle setpoint";
CM_ SG_ 2550628361 Current_setpoint_24 "The actual current setpoint";
CM_ SG_ 2550628361 Voltage_setpoint_24 "The actual voltage setpoint";
CM_ SG_ 2550628361 Frequency_setpoint_24 "The actual frequency setpoint";
CM_ SG_ 2550595680 Keep_Alive_Enable_24 "If set to 1, module will expect to receive this message every second repeatedly, or it will stop operation";
CM_ SG_ 2550595648 Converter_ON_24 "Enable the converter.";
CM_ SG_ 2550595648 PWM_ON_24 "Enable the PWM control mode.";
CM_ SG_ 2550595648 DC_Current_feedback_ON_24 "Enable the DC current loop";
CM_ SG_ 2550595648 AC_Current_feedback_ON_24 "Enable the AC current loop";
CM_ SG_ 2550595648 Buck_ON_24 "Enable the buck control mode.";
CM_ SG_ 2550595648 Boost_ON_24 "Enable the boost control mode.";
CM_ SG_ 2550595648 Rectifier_3ph_ON_24 "Enable the three-phase rectifier control mode.";
CM_ SG_ 2550595648 Inverter_1ph_ON_24 "Enable the single-phase inverter control mode.";
CM_ SG_ 2550595648 Rectifier_1ph_ON_24 "Enable the single-phase rectifier control mode.";
CM_ SG_ 2550595648 Boost_Neutral_ON_24 "Enable the boost control mode with neutral generation.";
CM_ SG_ 2550595648 Inverter_3ph_ON_24 "Enable the three-phase inverter control mode.";
CM_ SG_ 2550595648 Inverter_1ph_Sync_ON_24 "Single-phase inverter control mode with phase synchronization.";
CM_ SG_ 2550595648 Neutral_ON_24 "Open-loop neutral generation.";
CM_ SG_ 2550595648 Rectifier_1ph_Buck_ON_24 "Single-phase rectifier with buck on one leg.";
CM_ SG_ 2550595648 Inverter_1ph_Boost_ON_24 "Single-phase inverter with boost on one leg.";
CM_ SG_ 2550595648 Rectifier_Distributed_ON_24 "Single-phase (floating) distributed rectifier";
CM_ SG_ 2550595648 MPPT_buck_ON_24 "MPPT buck";
CM_ SG_ 2550595648 MPPT_boost_ON_24 "MPPT boost";
CM_ SG_ 2550595648 Buck_2p_float_ON_24 "Boost on L1 and L2. Floating L3 (high-impedance)";
CM_ SG_ 2550595648 Inverter_1ph_Distributed_ON_24 "Single-phase inverter mode distributed";
CM_ SG_ 2550595664 Clear_Interlock_24 "Clears the converter interlock";
CM_ SG_ 2550595664 Reset_Processor_24 "Reset the converter DSP";
CM_ SG_ 2550595664 Trip_Interlock_24 "Trip the inetrnal Interlock";
CM_ SG_ 2550595649 Reactive_current_setpoint_24 "This defines reactive current setpoint for 3-phase rectifier mode";
CM_ SG_ 2550595650 Phase_U_24 "The actual PWM duty cycle setpoint";
CM_ SG_ 2550595650 Phase_V_24 "The actual PWM duty cycle setpoint";
CM_ SG_ 2550595650 Phase_W_24 "The actual PWM duty cycle setpoint";
CM_ SG_ 2550595651 Current_setpoint_24 "Sets the output current setpoint. Active only when the current loop is enabled";
CM_ SG_ 2550595652 Voltage_setpoint_24 "Sets the output voltage setpoint. Active only when the voltage loop is enabled";
CM_ SG_ 2550595656 Frequency_setpoint_24 "Sets the frequency for single-phase and three-phase generator modes.";
CM_ SG_ 2550595657 Phase_setpoint_24 "Sets the phase for inverter control modes.";
CM_ SG_ 2550595653 Stack_position_24 "The converter position within the stack";
CM_ SG_ 2550595653 Stack_size_24 "How many PFC converters are in stack in total";
CM_ SG_ 2550595653 SN_number_24 "Unique module serial number";
CM_ SG_ 2550595632 Phase_voltage_min_24 "Minimum tolerated phase voltage";
CM_ SG_ 2550595632 Phase_voltage_max_24 "Maximum allowable phase voltage";
CM_ SG_ 2550595632 DC_voltage_min_24 "Minimum allowable dc voltage";
CM_ SG_ 2550595632 DC_voltage_max_24 "Maximum allowable dc voltage";
CM_ SG_ 2550595633 Phase_current_min_24 "Minimum allowable output current";
CM_ SG_ 2550595633 Phase_current_max_24 "Maximum allowable output current";
CM_ SG_ 2550595660 Group_ID_24 "Desired group ID for the device";
CM_ SG_ 2550628367 Group_ID_24 "Group ID of the device";
CM_ SG_ 2550595681 Factory_mode_24 "Customers MUST NOT USE this bit. If set to 1, module will enter in factory mode. ";
CM_ SG_ 2550595681 Silent_CAN_mode_24 "Customers MUST NOT USE this bit. If set to 1, module will enter in factory mode. ";
CM_ SG_ 2550595658 start_24 "Start automatic calibration. Multiplexer index must be 0!";
CM_ SG_ 2550595659 point_24 "Calibration point index.";
CM_ SG_ 2550595654 CRC_24 "Checksum of bytes 0 to 3, CRC-CCITT, corresponding to qChecksum (www.qt.io)";
CM_ SG_ 2550595655 CRC_24 "Checksum of bytes 0 to 3, CRC-CCITT, corresponding to qChecksum (www.qt.io)";
CM_ SG_ 2550628438 Current_U_High_24 "This flag is set if a hight current on U tripped the internal interlock";
CM_ SG_ 2550628438 Current_U_Low_24 "This flag is set if a low current on U tripped the internal interlock";
CM_ SG_ 2550628438 Current_V_High_24 "This flag is set if a hight current on V tripped the internal interlock";
CM_ SG_ 2550628438 Current_V_Low_24 "This flag is set if a low current on V tripped the internal interlock";
CM_ SG_ 2550628438 Current_W_High_24 "This flag is set if a hight current on W tripped the internal interlock";
CM_ SG_ 2550628438 Current_W_Low_24 "This flag is set if a low current on W tripped the internal interlock";
CM_ SG_ 2550628438 Voltage_DC_24 "This flag is set if a voltage on DC tripped the internal interlock";
CM_ SG_ 2550628438 Reboot_24 "This flag is set if a reboot tripped the internal interlock";
CM_ SG_ 2550628438 Unknown_24 "This flag the reason for the internal interlock is unknown";

BA_DEF_ BO_ "SystemMessageLongSymbol" STRING;

BA_ "SystemMessageLongSymbol" BO_ 2550595649 "AFE_Reactive_Current_Setpoint_Control_24";
BA_ "SystemMessageLongSymbol" BO_ 2550595656 "AFE_Frequency_Setpoint_Control_24";
BA_ "SystemMessageLongSymbol" BO_ 2550595696 "AFE_Rectifier_Setpoint_Control_24";
BA_ "SystemMessageLongSymbol" BO_ 2550595654 "_AFE_Calibration_Offset_Update_24";

VAL_ 2550628352 Device_type_24 7 "AFE";
VAL_ 2550628358 Protection_trip_internal_24 1 "fault";
VAL_ 2550628358 Protection_trip_external_24 1 "fault";
VAL_ 2550628358 Phase_U_overcurrent_24 1 "fault";
VAL_ 2550628358 Phase_U_overvoltage_24 1 "fault";
VAL_ 2550628358 Phase_U_undervoltage_24 1 "fault";
VAL_ 2550628358 Phase_V_overvoltage_24 1 "fault";
VAL_ 2550628358 Phase_V_undervoltage_24 1 "fault";
VAL_ 2550628358 Phase_V_overcurrent_24 1 "fault";
VAL_ 2550628358 Phase_W_overvoltage_24 1 "fault";
VAL_ 2550628358 Phase_W_undervoltage_24 1 "fault";
VAL_ 2550628358 Phase_W_overcurrent_24 1 "fault";
VAL_ 2550628358 DC_undervoltage_24 1 "fault";
VAL_ 2550628358 DC_overvoltage_24 1 "fault";
VAL_ 2550628358 MOSFET_overtemperature_24 1 "fault";
VAL_ 2550628358 Inductor_overtemperature_24 1 "fault";
VAL_ 2550628358 Keep_Alive_not_served_24 1 "fault";
VAL_ 2550628358 PLL_not_locked_24 1 "fault";
VAL_ 2550628358 NFO_24 1 "fault";
VAL_ 2550628358 Measurement_system_failure_24 1 "fault";
VAL_ 2550628358 EEPROM_failure_24 1 "fault";
VAL_ 2550628358 System_24 1 "fault";
VAL_ 2550628438 Current_U_High_24 1 "fault";
VAL_ 2550628438 Current_U_Low_24 1 "fault";
VAL_ 2550628438 Current_V_High_24 1 "fault";
VAL_ 2550628438 Current_V_Low_24 1 "fault";
VAL_ 2550628438 Current_W_High_24 1 "fault";
VAL_ 2550628438 Current_W_Low_24 1 "fault";
VAL_ 2550628438 Voltage_DC_24 1 "fault";
VAL_ 2550628438 Reboot_24 1 "fault";
VAL_ 2550628438 Unknown_24 1 "fault";
SIG_VALTYPE_ 2550628433 Current_U_24 : 1;
SIG_VALTYPE_ 2550628433 Current_V_24 : 1;
SIG_VALTYPE_ 2550628433 Current_W_24 : 1;
SIG_VALTYPE_ 2550628433 Voltage_U_24 : 1;
SIG_VALTYPE_ 2550628433 Voltage_V_24 : 1;
SIG_VALTYPE_ 2550628433 Voltage_W_24 : 1;
SIG_VALTYPE_ 2550628433 Voltage_DC_24 : 1;
SIG_VALTYPE_ 2550628434 Current_U_24 : 1;
SIG_VALTYPE_ 2550628434 Current_V_24 : 1;
SIG_VALTYPE_ 2550628434 Current_W_24 : 1;
SIG_VALTYPE_ 2550628434 Voltage_U_24 : 1;
SIG_VALTYPE_ 2550628434 Voltage_V_24 : 1;
SIG_VALTYPE_ 2550628434 Voltage_W_24 : 1;
SIG_VALTYPE_ 2550628434 Voltage_DC_24 : 1;
